AUTOSAR XML (schema 4-3-0)
package /App_Diag
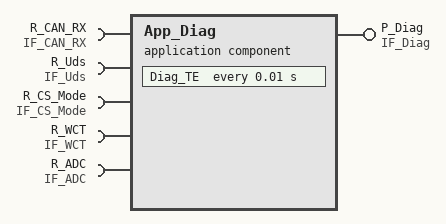
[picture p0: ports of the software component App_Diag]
  application sw component type App_Diag
    provide port P_Diag: nonqueued-sender-com-spec=Diag_STR, provided-interface=IF_Diag
    5 x require port:
      R_CAN_RX: nonqueued-receiver-com-spec=CAN_RX_STR, required-interface=IF_CAN_RX
      R_Uds: nonqueued-receiver-com-spec=Uds_STR, required-interface=IF_Uds
      R_CS_Mode: client-com-spec=ModeInit, required-interface=IF_CS_Mode
      R_WCT: nonqueued-receiver-com-spec=WCT_STR, required-interface=IF_WCT
      R_ADC: nonqueued-receiver-com-spec=ADC_STR, required-interface=IF_ADC
    behavior InternalBehavior: data-type-mapping=DataTypeMappingSet_WPC
      timing event TE_Diag_TE: start-on-event=Diag_TE, period=0.01
      runnable Diag_TE: symbol=Diag_TE_Runnable
        data-receive-point-by-arguments:
          4 x access, all with scope=COMMUNICATION-INTER-ECU:
            DRPBA_Diag_TE_R_ADC_ADC_STR: accessed-variable=R_ADC.ADC_STR
            DRPBA_Diag_TE_R_WCT_WCT_STR_ALL: accessed-variable=R_WCT.WCT_STR
            DRPBA_Diag_TE_R_Uds_Uds_STR: accessed-variable=R_Uds.Uds_STR
            DRPBA_Diag_TE_R_CAN_RX_CAN_RX_STR: accessed-variable=R_CAN_RX.CAN_RX_STR
        data-send-points:
          access DSP_Diag_TE_IF_Diag_Diag_STR: accessed-variable=P_Diag.Diag_STR, scope=COMMUNICATION-INTER-ECU
        sync call SSCP_Diag_TE_R_CS_Mode_ApplicationInit: operation=R_CS_Mode.ApplicationInit
        sync call SSCP_Diag_TE_R_CS_Mode_ModeInit: operation=R_CS_Mode.ModeInit
        sync call SSCP_Diag_TE_R_CS_Mode_NvMInit: operation=R_CS_Mode.NvMInit
  sender receiver interface IF_Diag  # NFC SWC Output
    data Diag_STR: type=IDT_Diag_STR
